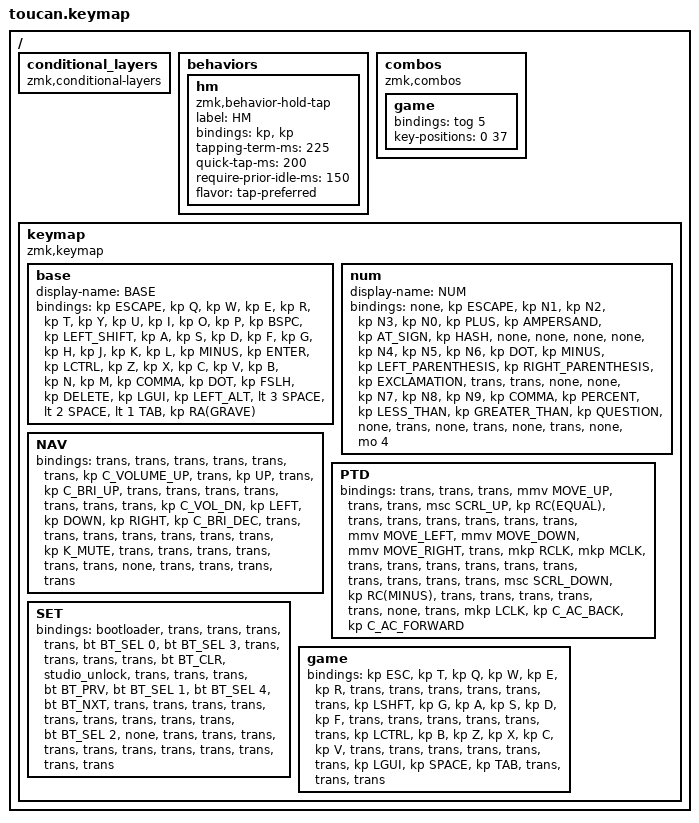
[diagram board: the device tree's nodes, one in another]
#include <behaviors.dtsi>
#include <dt-bindings/zmk/bt.h>
#include <dt-bindings/zmk/keys.h>
#include <dt-bindings/zmk/pointing.h>

#define BASE 0
#define NAV  1
#define SYM  2
#define ADJ  3

/ {
    conditional_layers { compatible = "zmk,conditional-layers"; };

    behaviors {
        hm: hm {
            compatible = "zmk,behavior-hold-tap";
            label = "HM";
            bindings = <&kp>, <&kp>;

            #binding-cells = <2>;
            tapping-term-ms = <225>;
            quick-tap-ms = <200>;
            require-prior-idle-ms = <150>;
            flavor = "tap-preferred";
        };
    };

    combos {
        compatible = "zmk,combos";

        game {
            bindings = <&tog 5>;
            key-positions = <0 37>;
        };
    };

    keymap {
        compatible = "zmk,keymap";

        base {
            display-name = "BASE";
            bindings = <
&kp ESCAPE  &kp Q  &kp W  &kp E  &kp R  &kp T  &kp Y  &kp U  &kp I  &kp O  &kp P  &kp BSPC  &kp LEFT_SHIFT  &kp A  &kp S  &kp D  &kp F  &kp G  &kp H  &kp J  &kp K  &kp L  &kp MINUS  &kp ENTER  &kp LCTRL  &kp Z  &kp X  &kp C  &kp V  &kp B  &kp N  &kp M  &kp COMMA  &kp DOT  &kp FSLH  &kp DELETE  &kp LGUI  &kp LEFT_ALT  &lt 3 SPACE  &lt 2 SPACE  &lt 1 TAB  &kp RA(GRAVE)
            >;
        };

        num {
            display-name = "NUM";
            bindings = <
&none  &kp ESCAPE  &kp N1  &kp N2  &kp N3  &kp N0  &kp PLUS  &kp AMPERSAND  &kp AT_SIGN  &kp HASH  &none  &none  &none  &none  &kp N4  &kp N5  &kp N6  &kp DOT  &kp MINUS  &kp LEFT_PARENTHESIS  &kp RIGHT_PARENTHESIS  &kp EXCLAMATION  &trans  &trans  &none  &none  &kp N7  &kp N8  &kp N9  &kp COMMA  &kp PERCENT  &kp LESS_THAN  &kp GREATER_THAN  &kp QUESTION  &none  &trans  &none  &trans  &none  &trans  &none  &mo 4
            >;
        };

        NAV {
            bindings = <
&trans  &trans  &trans  &trans  &trans  &trans  &kp C_VOLUME_UP  &trans  &kp UP  &trans  &kp C_BRI_UP  &trans  &trans  &trans  &trans  &trans  &trans  &trans  &kp C_VOL_DN  &kp LEFT  &kp DOWN  &kp RIGHT  &kp C_BRI_DEC  &trans  &trans  &trans  &trans  &trans  &trans  &trans  &kp K_MUTE  &trans  &trans  &trans  &trans  &trans  &trans  &none  &trans  &trans  &trans  &trans
            >;
        };

        PTD {
            bindings = <
&trans  &trans  &trans  &mmv MOVE_UP  &trans  &trans  &msc SCRL_UP  &kp RC(EQUAL)  &trans  &trans  &trans  &trans  &trans  &trans  &mmv MOVE_LEFT  &mmv MOVE_DOWN  &mmv MOVE_RIGHT  &trans  &mkp RCLK  &mkp MCLK  &trans  &trans  &trans  &trans  &trans  &trans  &trans  &trans  &trans  &trans  &msc SCRL_DOWN  &kp RC(MINUS)  &trans  &trans  &trans  &trans  &trans  &none  &trans  &mkp LCLK  &kp C_AC_BACK  &kp C_AC_FORWARD
            >;
        };

        SET {
            bindings = <
&bootloader  &trans  &trans  &trans  &trans  &bt BT_SEL 0  &bt BT_SEL 3  &trans  &trans  &trans  &trans  &bt BT_CLR  &studio_unlock  &trans  &trans  &trans  &bt BT_PRV  &bt BT_SEL 1  &bt BT_SEL 4  &bt BT_NXT  &trans  &trans  &trans  &trans  &trans  &trans  &trans  &trans  &trans  &bt BT_SEL 2  &none  &trans  &trans  &trans  &trans  &trans  &trans  &trans  &trans  &trans  &trans  &trans
            >;
        };

        game {
            bindings = <
&kp ESC  &kp T  &kp Q  &kp W  &kp E  &kp R  &trans  &trans  &trans  &trans  &trans  &trans  &kp LSHFT  &kp G  &kp A  &kp S  &kp D  &kp F  &trans  &trans  &trans  &trans  &trans  &trans  &kp LCTRL  &kp B  &kp Z  &kp X  &kp C  &kp V  &trans  &trans  &trans  &trans  &trans  &trans  &kp LGUI  &kp SPACE  &kp TAB  &trans  &trans  &trans
            >;
        };
    };
};
